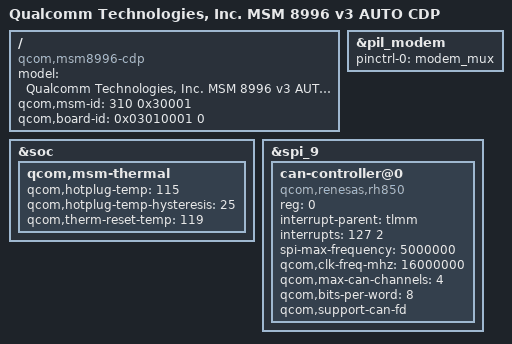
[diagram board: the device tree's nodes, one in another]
/* Copyright (c) 2015-2016, 2018, The Linux Foundation. All rights reserved.
 *
 * This program is free software; you can redistribute it and/or modify
 * it under the terms of the GNU General Public License version 2 and
 * only version 2 as published by the Free Software Foundation.
 *
 * This program is distributed in the hope that it will be useful,
 * but WITHOUT ANY WARRANTY; without even the implied warranty of
 * MERCHANTABILITY or FITNESS FOR A PARTICULAR PURPOSE.  See the
 * GNU General Public License for more details.
 */

/dts-v1/;

#include "msm8996-v3.dtsi"
#include "msm8996-pm8994.dtsi"
#include "msm8996-auto-cdp.dtsi"
#include "msm8996v3-auto.dtsi"

/ {
	model = "Qualcomm Technologies, Inc. MSM 8996 v3 AUTO CDP";
	compatible = "qcom,msm8996-cdp", "qcom,msm8996", "qcom,cdp";
	qcom,msm-id = <310 0x30001>;
	qcom,board-id = <0x03010001 0>;
};

&soc {
	qcom,msm-thermal {
		qcom,hotplug-temp = <115>;
		qcom,hotplug-temp-hysteresis = <25>;
		qcom,therm-reset-temp = <119>;
	};
};

&pil_modem {
	pinctrl-names = "default";
	pinctrl-0 = <&modem_mux>;
};

&spi_9 {
	status = "ok";
	can-controller@0 {
		compatible = "qcom,renesas,rh850";
		reg = <0>;
		interrupt-parent = <&tlmm>;
		interrupts = <127 2>;
		spi-max-frequency = <5000000>;
		qcom,clk-freq-mhz = <16000000>;
		qcom,max-can-channels = <4>;
		qcom,bits-per-word = <8>;
		qcom,support-can-fd;
	};
};
